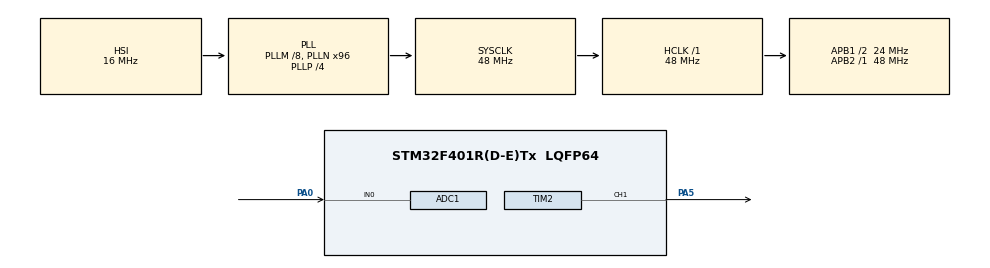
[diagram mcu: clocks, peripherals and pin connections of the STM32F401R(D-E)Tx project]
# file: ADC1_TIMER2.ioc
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ADC1.Channel-5\#ChannelRegularConversion=ADC_CHANNEL_0
ADC1.ClockPrescaler=ADC_CLOCK_SYNC_PCLK_DIV2
ADC1.ContinuousConvMode=ENABLE
ADC1.DMAContinuousRequests=DISABLE
ADC1.DataAlign=ADC_DATAALIGN_RIGHT
ADC1.DiscontinuousConvMode=DISABLE
ADC1.EOCSelection=ADC_EOC_SEQ_CONV
ADC1.EnableAnalogWatchDog=false
ADC1.ExternalTrigConvEdge=ADC_EXTERNALTRIGCONVEDGE_NONE
ADC1.InjNumberOfConversion=0
ADC1.NbrOfConversion=1
ADC1.NbrOfConversionFlag=1
ADC1.Rank-5\#ChannelRegularConversion=1
ADC1.Resolution=ADC_RESOLUTION_12B
ADC1.SamplingTime-5\#ChannelRegularConversion=ADC_SAMPLETIME_144CYCLES
ADC1.ScanConvMode=DISABLE
ADC1.master=1
Dma.ADC1.0.Direction=DMA_PERIPH_TO_MEMORY
Dma.ADC1.0.FIFOMode=DMA_FIFOMODE_DISABLE
Dma.ADC1.0.Instance=DMA2_Stream0
Dma.ADC1.0.MemDataAlignment=DMA_MDATAALIGN_WORD
Dma.ADC1.0.MemInc=DMA_MINC_DISABLE
Dma.ADC1.0.Mode=DMA_CIRCULAR
Dma.ADC1.0.PeriphDataAlignment=DMA_PDATAALIGN_WORD
Dma.ADC1.0.PeriphInc=DMA_PINC_DISABLE
Dma.ADC1.0.Priority=DMA_PRIORITY_MEDIUM
Dma.Request0=ADC1
Dma.Request1=TIM2_CH1
Dma.TIM2_CH1.1.Direction=DMA_MEMORY_TO_PERIPH
Dma.TIM2_CH1.1.FIFOMode=DMA_FIFOMODE_DISABLE
Dma.TIM2_CH1.1.Instance=DMA1_Stream5
Dma.TIM2_CH1.1.MemDataAlignment=DMA_MDATAALIGN_WORD
Dma.TIM2_CH1.1.MemInc=DMA_MINC_DISABLE
Dma.TIM2_CH1.1.Mode=DMA_CIRCULAR
Dma.TIM2_CH1.1.PeriphDataAlignment=DMA_PDATAALIGN_WORD
Dma.TIM2_CH1.1.PeriphInc=DMA_PINC_DISABLE
Dma.TIM2_CH1.1.Priority=DMA_PRIORITY_MEDIUM
Mcu.Family=STM32F4
Mcu.Name=STM32F401R(D-E)Tx
Mcu.Package=LQFP64
NVIC.DMA1_Stream5_IRQn=true\:0\:0\:false\:false\:true
NVIC.DMA2_Stream0_IRQn=true\:0\:0\:false\:false\:true
NVIC.PriorityGroup=NVIC_PRIORITYGROUP_4
PA0-WKUP.Signal=ADCx_IN0
PA5.Signal=S_TIM2_CH1_ETR
ProjectManager.HeapSize=0x200
ProjectManager.StackSize=0x400
ProjectManager.TargetToolchain=EWARM
RCC.48MHZClocksFreq_Value=48000000
RCC.AHBFreq_Value=48000000
RCC.APB1CLKDivider=RCC_HCLK_DIV2
RCC.APB1Freq_Value=24000000
RCC.APB1TimFreq_Value=48000000
RCC.APB2Freq_Value=48000000
RCC.APB2TimFreq_Value=48000000
RCC.CortexFreq_Value=48000000
RCC.HCLKFreq_Value=48000000
RCC.HSE_VALUE=25000000
RCC.HSI_VALUE=16000000
RCC.LSE_VALUE=32768
RCC.PLLM=8
RCC.PLLN=96
RCC.PLLP=RCC_PLLP_DIV4
RCC.SYSCLKFreq_VALUE=48000000
RCC.SYSCLKSource=RCC_SYSCLKSOURCE_PLLCLK
RCC.VCOOutputFreq_Value=192000000
SH.ADCx_IN0.0=ADC1_IN0,IN0
SH.S_TIM2_CH1_ETR.0=TIM2_CH1,PWM Generation1 CH1
TIM2.Period=4800
VP_TIM2_VS_ClockSourceINT.Mode=Internal
board=ADC1_TIMER2

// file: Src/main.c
/**
  ******************************************************************************
  * File Name          : main.c
  * Description        : Main program body
  ******************************************************************************
  *
  * COPYRIGHT(c) 2016 STMicroelectronics
  *
  * Redistribution and use in source and binary forms, with or without modification,
  * are permitted provided that the following conditions are met:
  *   1. Redistributions of source code must retain the above copyright notice,
  *      this list of conditions and the following disclaimer.
  *   2. Redistributions in binary form must reproduce the above copyright notice,
  *      this list of conditions and the following disclaimer in the documentation
  *      and/or other materials provided with the distribution.
  *   3. Neither the name of STMicroelectronics nor the names of its contributors
  *      may be used to endorse or promote products derived from this software
  *      without specific prior written permission.
  *
  * THIS SOFTWARE IS PROVIDED BY THE COPYRIGHT HOLDERS AND CONTRIBUTORS "AS IS"
  * AND ANY EXPRESS OR IMPLIED WARRANTIES, INCLUDING, BUT NOT LIMITED TO, THE
  * IMPLIED WARRANTIES OF MERCHANTABILITY AND FITNESS FOR A PARTICULAR PURPOSE ARE
  * DISCLAIMED. IN NO EVENT SHALL THE COPYRIGHT HOLDER OR CONTRIBUTORS BE LIABLE
  * FOR ANY DIRECT, INDIRECT, INCIDENTAL, SPECIAL, EXEMPLARY, OR CONSEQUENTIAL
  * DAMAGES (INCLUDING, BUT NOT LIMITED TO, PROCUREMENT OF SUBSTITUTE GOODS OR
  * SERVICES; LOSS OF USE, DATA, OR PROFITS; OR BUSINESS INTERRUPTION) HOWEVER
  * CAUSED AND ON ANY THEORY OF LIABILITY, WHETHER IN CONTRACT, STRICT LIABILITY,
  * OR TORT (INCLUDING NEGLIGENCE OR OTHERWISE) ARISING IN ANY WAY OUT OF THE USE
  * OF THIS SOFTWARE, EVEN IF ADVISED OF THE POSSIBILITY OF SUCH DAMAGE.
  *
  ******************************************************************************
  */
#include "stm32f4xx_hal.h"

ADC_HandleTypeDef hadc1;
DMA_HandleTypeDef hdma_adc1;

TIM_HandleTypeDef htim2;
DMA_HandleTypeDef hdma_tim2_ch1;

/* USER CODE BEGIN PV */
/* Private variables ---------------------------------------------------------*/
uint32_t dma_data = 0;
/* USER CODE END PV */

void SystemClock_Config(void);
void Error_Handler(void);
static void MX_GPIO_Init(void);
static void MX_DMA_Init(void);
static void MX_ADC1_Init(void);
static void MX_TIM2_Init(void);

void HAL_TIM_MspPostInit(TIM_HandleTypeDef *htim);

/* USER CODE BEGIN PFP */
/* Private function prototypes -----------------------------------------------*/

/* USER CODE END PFP */

int main(void)
{

  /* MCU Configuration----------------------------------------------------------*/

  /* Reset of all peripherals, Initializes the Flash interface and the Systick. */
  HAL_Init();

  /* Configure the system clock */
  SystemClock_Config();

  /* Initialize all configured peripherals */
  MX_GPIO_Init();
  MX_DMA_Init();
  MX_ADC1_Init();
  MX_TIM2_Init();

  /* Infinite loop */
  while (1)
  {

  /* USER CODE BEGIN 3 */

    HAL_ADC_Start(&hadc1);
    while(__HAL_ADC_GET_FLAG(&hadc1, ADC_FLAG_EOC) == RESET);
    HAL_ADC_Start_DMA(&hadc1, &dma_data/*0x4001204C*/, 8);
    /*
    PERIPH_BASE = 0x40000000
    APB2PERIPH_BASE = (PERIPH_BASE + 0x00010000)
    ADC1_BASE = (APB2PERIPH_BASE + 0x2000)
    DR = 0x4C
    DMA Address = ADC1_BASE(APB2PERIPH_BASE(PERIPH_BASE(0x40000000) + 0x00010000) + 0x2000) + DR(0x4C) = 0x4001204C
    */
    HAL_TIM_PWM_Start_DMA(&htim2, TIM_CHANNEL_1, &dma_data/*0x40000034*/, 8);
    /*
    PERIPH_BASE = 0x40000000
    APB1PERIPH_BASE = PERIPH_BASE
    TIM2_BASE = (APB1PERIPH_BASE + 0x0000)
    CCR1 = 0x34
    DMA Address = TIM2_BASE(APB1PERIPH_BASE(PERIPH_BASE(0x40000000)) + 0x0000) + CCR1(0x34) = 0x40000034
    */
    HAL_ADC_Stop_DMA(&hadc1);

	}
  /* USER CODE END 3 */

}

/** System Clock Configuration
*/
void SystemClock_Config(void)
{

  RCC_OscInitTypeDef RCC_OscInitStruct;
  RCC_ClkInitTypeDef RCC_ClkInitStruct;

  __HAL_RCC_PWR_CLK_ENABLE();

  __HAL_PWR_VOLTAGESCALING_CONFIG(PWR_REGULATOR_VOLTAGE_SCALE2);

  RCC_OscInitStruct.OscillatorType = RCC_OSCILLATORTYPE_HSI;
  RCC_OscInitStruct.HSIState = RCC_HSI_ON;
  RCC_OscInitStruct.HSICalibrationValue = 16;
  RCC_OscInitStruct.PLL.PLLState = RCC_PLL_ON;
  RCC_OscInitStruct.PLL.PLLSource = RCC_PLLSOURCE_HSI;
  RCC_OscInitStruct.PLL.PLLM = 8;
  RCC_OscInitStruct.PLL.PLLN = 96;
  RCC_OscInitStruct.PLL.PLLP = RCC_PLLP_DIV4;
  RCC_OscInitStruct.PLL.PLLQ = 4;
  if (HAL_RCC_OscConfig(&RCC_OscInitStruct) != HAL_OK)
  {
    Error_Handler();
  }

  RCC_ClkInitStruct.ClockType = RCC_CLOCKTYPE_HCLK|RCC_CLOCKTYPE_SYSCLK
                              |RCC_CLOCKTYPE_PCLK1|RCC_CLOCKTYPE_PCLK2;
  RCC_ClkInitStruct.SYSCLKSource = RCC_SYSCLKSOURCE_PLLCLK;
  RCC_ClkInitStruct.AHBCLKDivider = RCC_SYSCLK_DIV1;
  RCC_ClkInitStruct.APB1CLKDivider = RCC_HCLK_DIV2;
  RCC_ClkInitStruct.APB2CLKDivider = RCC_HCLK_DIV1;
  if (HAL_RCC_ClockConfig(&RCC_ClkInitStruct, FLASH_LATENCY_1) != HAL_OK)
  {
    Error_Handler();
  }

  HAL_SYSTICK_Config(HAL_RCC_GetHCLKFreq()/1000);

  HAL_SYSTICK_CLKSourceConfig(SYSTICK_CLKSOURCE_HCLK);

  /* SysTick_IRQn interrupt configuration */
  HAL_NVIC_SetPriority(SysTick_IRQn, 0, 0);
}

/* ADC1 init function */
static void MX_ADC1_Init(void)
{

  ADC_ChannelConfTypeDef sConfig;

    /**Configure the global features of the ADC (Clock, Resolution, Data Alignment and number of conversion)
    */
  hadc1.Instance = ADC1;
  hadc1.Init.ClockPrescaler = ADC_CLOCK_SYNC_PCLK_DIV2;
  hadc1.Init.Resolution = ADC_RESOLUTION_12B;
  hadc1.Init.ScanConvMode = DISABLE;
  hadc1.Init.ContinuousConvMode = ENABLE;
  hadc1.Init.DiscontinuousConvMode = DISABLE;
  hadc1.Init.ExternalTrigConvEdge = ADC_EXTERNALTRIGCONVEDGE_NONE;
  hadc1.Init.DataAlign = ADC_DATAALIGN_RIGHT;
  hadc1.Init.NbrOfConversion = 1;
  hadc1.Init.DMAContinuousRequests = DISABLE;
  hadc1.Init.EOCSelection = ADC_EOC_SEQ_CONV;
  if (HAL_ADC_Init(&hadc1) != HAL_OK)
  {
    Error_Handler();
  }

    /**Configure for the selected ADC regular channel its corresponding rank in the sequencer and its sample time.
    */
  sConfig.Channel = ADC_CHANNEL_0;
  sConfig.Rank = 1;
  sConfig.SamplingTime = ADC_SAMPLETIME_144CYCLES;
  if (HAL_ADC_ConfigChannel(&hadc1, &sConfig) != HAL_OK)
  {
    Error_Handler();
  }
}

/* TIM2 init function */
static void MX_TIM2_Init(void)
{

  TIM_ClockConfigTypeDef sClockSourceConfig;
  TIM_MasterConfigTypeDef sMasterConfig;
  TIM_OC_InitTypeDef sConfigOC;

  htim2.Instance = TIM2;
  htim2.Init.Prescaler = 0;
  htim2.Init.CounterMode = TIM_COUNTERMODE_UP;
  htim2.Init.Period = 4800;
  htim2.Init.ClockDivision = TIM_CLOCKDIVISION_DIV1;
  if (HAL_TIM_Base_Init(&htim2) != HAL_OK)
  {
    Error_Handler();
  }

  sClockSourceConfig.ClockSource = TIM_CLOCKSOURCE_INTERNAL;
  if (HAL_TIM_ConfigClockSource(&htim2, &sClockSourceConfig) != HAL_OK)
  {
    Error_Handler();
  }

  if (HAL_TIM_PWM_Init(&htim2) != HAL_OK)
  {
    Error_Handler();
  }

  sMasterConfig.MasterOutputTrigger = TIM_TRGO_RESET;
  sMasterConfig.MasterSlaveMode = TIM_MASTERSLAVEMODE_DISABLE;
  if (HAL_TIMEx_MasterConfigSynchronization(&htim2, &sMasterConfig) != HAL_OK)
  {
    Error_Handler();
  }

  sConfigOC.OCMode = TIM_OCMODE_PWM1;
  sConfigOC.Pulse = 0;
  sConfigOC.OCPolarity = TIM_OCPOLARITY_HIGH;
  sConfigOC.OCFastMode = TIM_OCFAST_DISABLE;
  if (HAL_TIM_PWM_ConfigChannel(&htim2, &sConfigOC, TIM_CHANNEL_1) != HAL_OK)
  {
    Error_Handler();
  }

  HAL_TIM_MspPostInit(&htim2);
  __HAL_TIM_ENABLE(&htim2);
}

static void MX_DMA_Init(void)
{
  /* DMA controller clock enable */
  __HAL_RCC_DMA2_CLK_ENABLE();
  __HAL_RCC_DMA1_CLK_ENABLE();

  /* DMA interrupt init */
  /* DMA1_Stream5_IRQn interrupt configuration */
  HAL_NVIC_SetPriority(DMA1_Stream5_IRQn, 0, 0);
  HAL_NVIC_EnableIRQ(DMA1_Stream5_IRQn);
  /* DMA2_Stream0_IRQn interrupt configuration */
  HAL_NVIC_SetPriority(DMA2_Stream0_IRQn, 0, 0);
  HAL_NVIC_EnableIRQ(DMA2_Stream0_IRQn);

}

/** Pinout Configuration
*/
static void MX_GPIO_Init(void)
{

  /* GPIO Ports Clock Enable */
  __HAL_RCC_GPIOA_CLK_ENABLE();

}

void Error_Handler(void)
{
  while(1)
  {
  }
}

/************************ (C) COPYRIGHT STMicroelectronics *****END OF FILE****/
